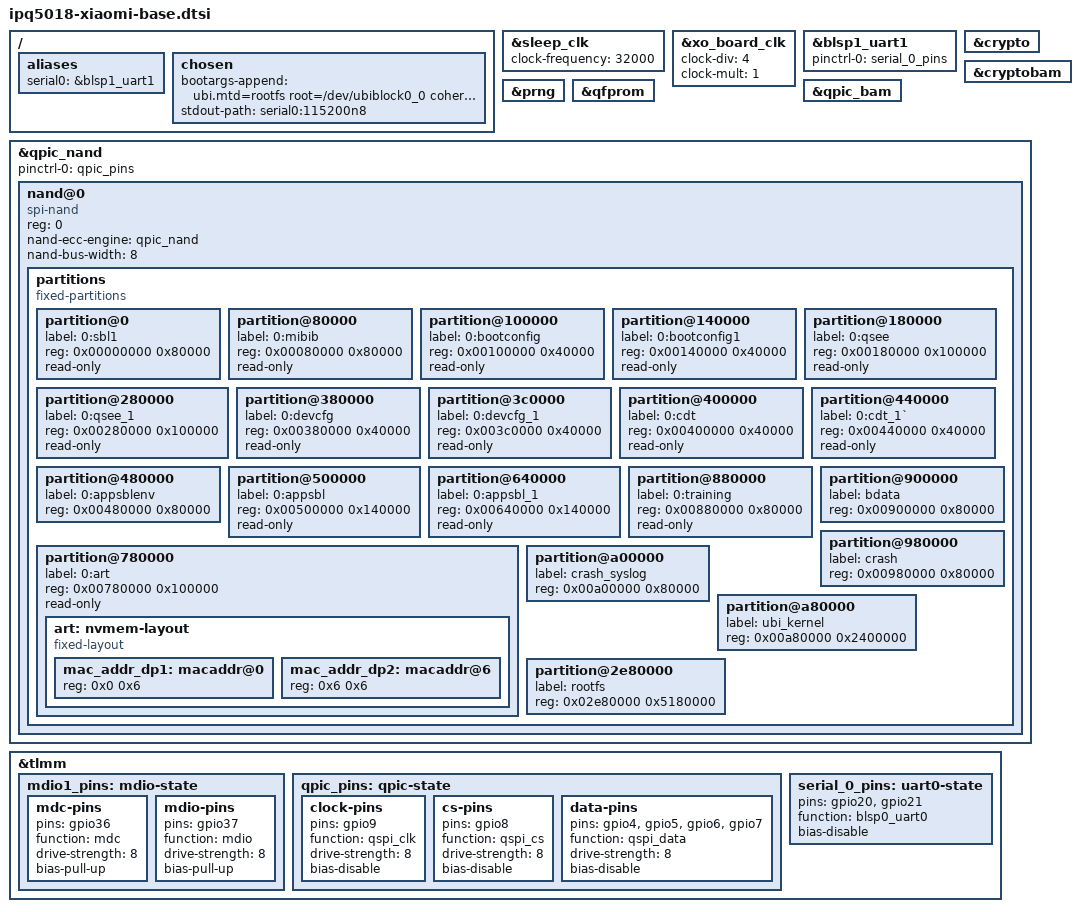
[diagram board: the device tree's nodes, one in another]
#include "ipq5018.dtsi"
#include "ipq5018-ess.dtsi"

#include <dt-bindings/gpio/gpio.h>
#include <dt-bindings/input/input.h>
#include <dt-bindings/leds/common.h>

/ {

	aliases {
		serial0 = &blsp1_uart1;
	};

	chosen {
		/* Xiaomi's U-boot sets bootargs to:
		 * ubi.mtd=rootfs_1 root=mtd:ubi_rootfs rootfstype=squashfs rootwait uart_en=1
		 * so we need to override and set ubi.mtd=rootfs
		 */
		bootargs-append = " ubi.mtd=rootfs root=/dev/ubiblock0_0 coherent_pool=2M";
		stdout-path = "serial0:115200n8";
	};
};

&sleep_clk {
	clock-frequency = <32000>;
};

&xo_board_clk {
	clock-div = <4>;
	clock-mult = <1>;
};

&blsp1_uart1 {
	status = "okay";

	pinctrl-0 = <&serial_0_pins>;
	pinctrl-names = "default";
};

&crypto {
	status = "okay";
};

&cryptobam {
	status = "okay";
};

&prng {
	status = "okay";
};

&qfprom {
	status = "okay";
};

&qpic_bam {
	status = "okay";
};

&qpic_nand {
	pinctrl-0 = <&qpic_pins>;
	pinctrl-names = "default";
	status = "okay";

	nand@0 {
		compatible = "spi-nand";
		reg = <0>;
		nand-ecc-engine = <&qpic_nand>;
		nand-bus-width = <8>;

		partitions {
			compatible = "fixed-partitions";
			#address-cells = <1>;
			#size-cells = <1>;

			partition@0 {
				label = "0:sbl1";
				reg = <0x00000000 0x80000>;
				read-only;
			};

			partition@80000 {
				label = "0:mibib";
				reg = <0x00080000 0x80000>;
				read-only;
			};

			partition@100000 {
				label = "0:bootconfig";
				reg = <0x00100000 0x40000>;
				read-only;
			};

			partition@140000 {
				label = "0:bootconfig1";
				reg = <0x00140000 0x40000>;
				read-only;
			};

			partition@180000 {
				label = "0:qsee";
				reg = <0x00180000 0x100000>;
				read-only;
			};

			partition@280000 {
				label = "0:qsee_1";
				reg = <0x00280000 0x100000>;
				read-only;
			};

			partition@380000 {
				label = "0:devcfg";
				reg = <0x00380000 0x40000>;
				read-only;
			};

			partition@3c0000 {
				label = "0:devcfg_1";
				reg = <0x003c0000 0x40000>;
				read-only;
			};

			partition@400000 {
				label = "0:cdt";
				reg = <0x00400000 0x40000>;
				read-only;
			};

			partition@440000 {
				label = "0:cdt_1`";
				reg = <0x00440000 0x40000>;
				read-only;
			};

			partition@480000 {
				label = "0:appsblenv";
				reg = <0x00480000 0x80000>;
			};

			partition@500000 {
				label = "0:appsbl";
				reg = <0x00500000 0x140000>;
				read-only;
			};

			partition@640000 {
				label = "0:appsbl_1";
				reg = <0x00640000 0x140000>;
				read-only;
			};

			partition@780000 {
				label = "0:art";
				reg = <0x00780000 0x100000>;
				read-only;

				art: nvmem-layout {
					compatible = "fixed-layout";
					#address-cells = <1>;
					#size-cells = <1>;

					mac_addr_dp1: macaddr@0 {
						reg = <0x0 0x6>;
					};

					mac_addr_dp2: macaddr@6 {
						reg = <0x6 0x6>;
					};
				};
			};

			partition@880000 {
				label = "0:training";
				reg = <0x00880000 0x80000>;
				read-only;
			};

			partition@900000 {
				label = "bdata";
				reg = <0x00900000 0x80000>;
			};

			partition@980000 {
				label = "crash";
				reg = <0x00980000 0x80000>;
			};

			partition@a00000 {
				label = "crash_syslog";
				reg = <0x00a00000 0x80000>;
			};

			partition@a80000 {
				label = "ubi_kernel";
				reg = <0x00a80000 0x2400000>;
			};

			partition@2e80000 {
				label = "rootfs";
				reg = <0x02e80000 0x5180000>;
			};
		};
	};
};

&tlmm {
	mdio1_pins: mdio-state {
		mdc-pins {
			pins = "gpio36";
			function = "mdc";
			drive-strength = <8>;
			bias-pull-up;
		};

		mdio-pins {
			pins = "gpio37";
			function = "mdio";
			drive-strength = <8>;
			bias-pull-up;
		};
	};

	qpic_pins: qpic-state {
		clock-pins {
			pins = "gpio9";
			function = "qspi_clk";
			drive-strength = <8>;
			bias-disable;
		};

		cs-pins {
			pins = "gpio8";
			function = "qspi_cs";
			drive-strength = <8>;
			bias-disable;
		};

		data-pins {
			pins = "gpio4", "gpio5", "gpio6", "gpio7";
			function = "qspi_data";
			drive-strength = <8>;
			bias-disable;
		};
	};

	serial_0_pins: uart0-state {
		pins = "gpio20", "gpio21";
		function = "blsp0_uart0";
		bias-disable;
	};
};
